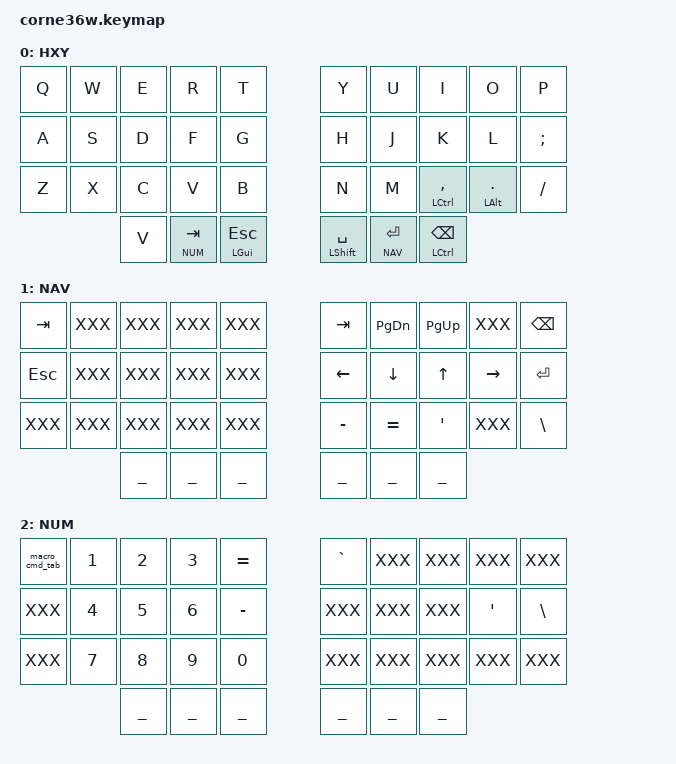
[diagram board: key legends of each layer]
#include <behaviors.dtsi>
#include <dt-bindings/zmk/keys.h>
#include <dt-bindings/zmk/bt.h>
#include <dt-bindings/zmk/outputs.h>
#include "36keys.h"

&sk {
  release-after-ms = <STICKY_KEY_TIMEOUT>;
};

&caps_word {
  continue-list = <UNDERSCORE MINUS BACKSPACE>;
};

&kscan0 {
  debounce-period = <14>;
};

&mt {
    tapping-term-ms = <100>; // This is the value already set by default
};

&lt {
    tapping-term-ms = <100>; // This is the value already set by default
};

/ {
  combos {
    #include "combos.dtsi"
  };

  macros {
   #include "macros.dtsi"
  };

  behaviors {

    skq: sticky_key_quick_release {
      compatible = "zmk,behavior-sticky-key";
      label = "STICKY_KEY_QUICK_RELEASE";
      #binding-cells = <1>;
      bindings = <&kp>;
      quick-release;
      release-after-ms = <STICKY_KEY_TIMEOUT>;
    };

    // Sticky key on tap, normal key on hold
    // Useful for modifier-clicking without the modifier remaining active
    nk: not_so_sticky_key {
      compatible = "zmk,behavior-hold-tap";
      label = "NOT_SO_STICKY_KEY";
      #binding-cells = <2>;
      tapping_term_ms = <200>;
      flavor = "tap-preferred";
      bindings = <&kp>, <&sk>;
    };

    // A hold-tap that activates without delay (like `&mo`)
    mo_tap: mo_with_tap {
      compatible = "zmk,behavior-hold-tap";
      label = "MO_WITH_TAP";
      #binding-cells = <2>;
      tapping_term_ms = <0>;
      retro-tap;
      flavor = "hold-preferred";
      bindings = <&mo>, <&kp>;
    };
  };

  /*
    LAYERS
      &mo - Momentary Layer switch
      &lt - Layer Tap - Enable layer when held, key when tapped
      &to - Enable layer permanently, disables all others but base
      &tog - Toggle layer until manually disabled
    
    OTHERS
      &kp - Key press, nothing more
      &mt - Mod-Tap - Key if held, different key if tapped
      &sk - Sticky Key - Key is pressed until another key is pressed (e.g sticky shift)
      &sl - Sticky layer - Same as &sk but with layers

  */
                                                     
  keymap {
    compatible = "zmk,keymap";

    base_layer {
      label = "HXY";
      bindings = <
        // ╭─────────────┬─────────────┬─────────────┬─────────────┬─────────────╮   ╭─────────────┬─────────────┬─────────────┬─────────────┬─────────────╮
             &kp Q         &kp W         &kp E        &kp R         &kp T              &kp Y         &kp U         &kp I         &kp O         &kp P
        // ├─────────────┼─────────────┼─────────────┼─────────────┼─────────────┤   ├─────────────┼─────────────┼─────────────┼─────────────┼─────────────┤
             &kp A         &kp S         &kp D         &kp F         &kp G             &kp H         &kp J         &kp K        &kp L         &kp SEMI
        // ├─────────────┼─────────────┼─────────────┼─────────────┼─────────────┤   ├─────────────┼─────────────┼─────────────┼─────────────┼─────────────┤
             &kp Z         &kp X         &kp C         &kp V              &kp B        &kp N         &kp M       &mt LCTRL COMMA &mt LALT DOT    &kp SLASH
        // ╰─────────────┴─────────────┴─────────────┼─────────────┼─────────────┤   ├─────────────┼─────────────┼─────────────┴─────────────┴─────────────╯
                                            &kp V      &lt NUM TAB   &mt LGUI ESC    &mt LSHIFT SPACE  &lt NAV ENTER	&mt LCTRL BSPC
        //                              ╰────────────┴─────────────┴─────────────╯   ╰─────────────┴─────────────┴─────────────╯
      >;                                // V is mirrored here because the pin is fried on MCU
    };

    nav_layer {
      label = "NAV";
      bindings = <
        // ╭─────────────┬─────────────┬─────────────┬─────────────┬─────────────╮   ╭─────────────┬─────────────┬─────────────┬─────────────┬─────────────╮
             &kp TAB           XXX            XXX           XXX           XXX           &kp TAB        &kp PG_DN     &kp PG_UP     XXX         &kp BSPC
        // ├─────────────┼─────────────┼─────────────┼─────────────┼─────────────┤   ├─────────────┼─────────────┼─────────────┼─────────────┼─────────────┤
             &kp ESC           XXX            XXX           XXX           XXX           &kp LEFT        &kp DOWN      &kp UP      &kp RIGHT     &kp ENTER
        // ├─────────────┼─────────────┼─────────────┼─────────────┼─────────────┤   ├─────────────┼─────────────┼─────────────┼─────────────┼─────────────┤
             XXX           XXX            XXX           XXX           XXX               &kp MINUS     &kp EQUAL     &kp SQT       XXX          &kp BACKSLASH
        // ╰─────────────┴─────────────┴─────────────┼─────────────┼─────────────┤   ├─────────────┼─────────────┼─────────────┴─────────────┴─────────────╯
                                          ___          ___           ___               ___           ___			___
        //                             ╰─────────────┴─────────────┴─────────────╯   ╰─────────────┴─────────────┴─────────────╯
      >;
    };
    
    num_layer {
      label = "NUM";
      bindings = <
        // ╭─────────────┬─────────────┬─────────────┬─────────────┬─────────────╮   ╭─────────────┬─────────────┬─────────────┬─────────────┬─────────────╮
           &macro_cmd_tab  &kp N1        &kp N2        &kp N3        &kp EQUAL         &kp GRAVE       XXX             XXX          XXX            XXX
        // ├─────────────┼─────────────┼─────────────┼─────────────┼─────────────┤   ├─────────────┼─────────────┼─────────────┼─────────────┼─────────────┤
             XXX           &kp N4        &kp N5        &kp N6        &kp MINUS         XXX             XXX            XXX            &kp SQT    &kp BACKSLASH
        // ├─────────────┼─────────────┼─────────────┼─────────────┼─────────────┤   ├─────────────┼─────────────┼─────────────┼─────────────┼─────────────┤
             XXX           &kp N7        &kp N8        &kp N9        &kp N0            XXX             XXX           XXX           XXX           XXX
        // ╰─────────────┴─────────────┴─────────────┼─────────────┼─────────────┤   ├─────────────┼─────────────┼─────────────┴─────────────┴─────────────╯
                                         ___            ___           ___               ___           ___ 		   ___
        //                             ╰─────────────┴─────────────┴─────────────╯   ╰─────────────┴─────────────┴─────────────╯
      >;
    };
  };
};
